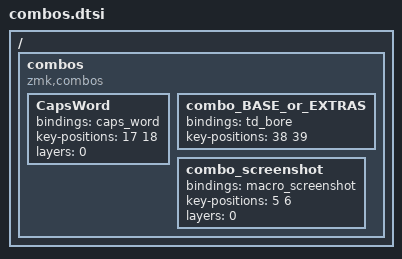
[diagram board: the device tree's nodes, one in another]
/ {
    combos {
        compatible = "zmk,combos";

        CapsWord {
            bindings = <&caps_word>;
            key-positions = <17 18>;
            layers = <0>;
        };

        combo_BASE_or_EXTRAS {
            bindings = <&td_bore>;
            key-positions = <38 39>;
        };

        combo_screenshot {
            bindings = <&macro_screenshot>;
            key-positions = <5 6>; // T + Y
            layers = <0>;
        };
    };
};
